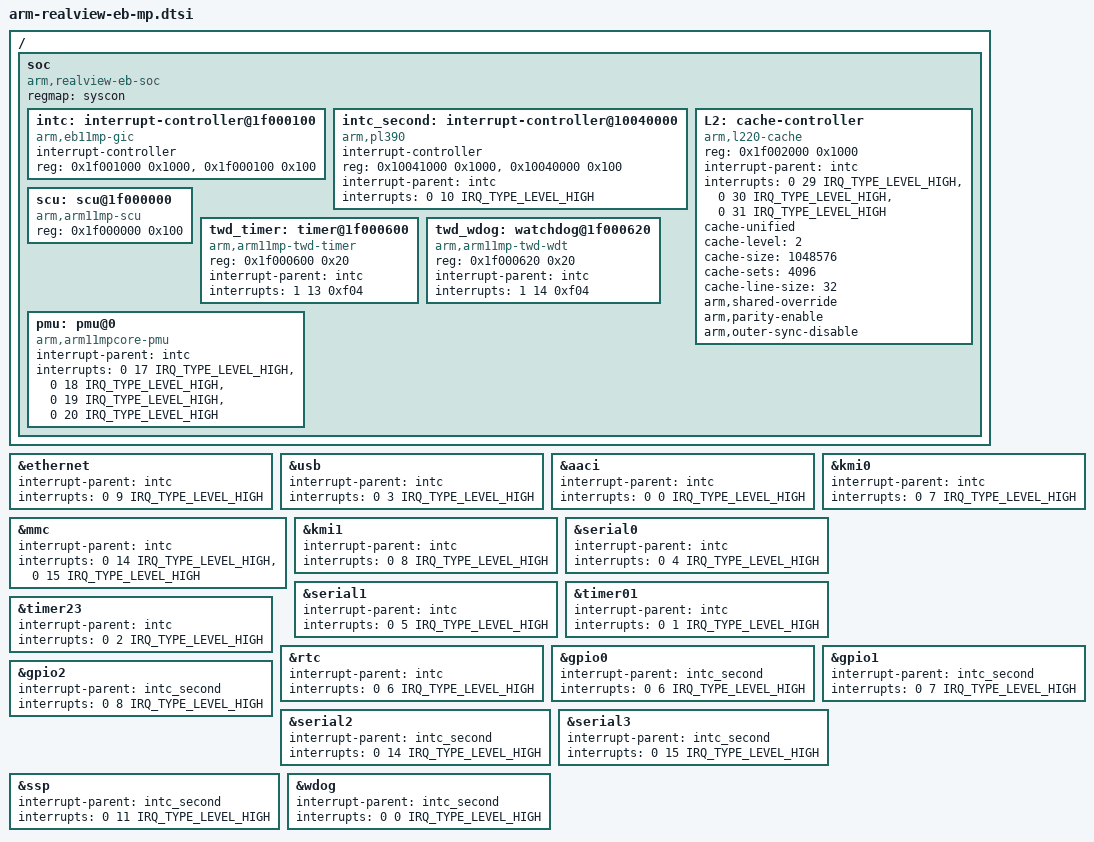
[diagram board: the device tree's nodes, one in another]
#include <dt-bindings/interrupt-controller/irq.h>
#include <dt-bindings/gpio/gpio.h>
#include "arm-realview-eb.dtsi"
/ {
	soc {
		#address-cells = <1>;
		#size-cells = <1>;
		compatible = "arm,realview-eb-soc", "simple-bus";
		regmap = <&syscon>;
		ranges;
		intc: interrupt-controller@1f000100 {
			compatible = "arm,eb11mp-gic";
			#interrupt-cells = <3>;
			#address-cells = <1>;
			interrupt-controller;
			reg = <0x1f001000 0x1000>,
			      <0x1f000100 0x100>;
		};
		intc_second: interrupt-controller@10040000 {
			compatible = "arm,pl390";
			#interrupt-cells = <3>;
			#address-cells = <1>;
			interrupt-controller;
			reg = <0x10041000 0x1000>,
			      <0x10040000 0x100>;
			interrupt-parent = <&intc>;
			interrupts = <0 10 IRQ_TYPE_LEVEL_HIGH>;
		};
		L2: cache-controller {
			compatible = "arm,l220-cache";
			reg = <0x1f002000 0x1000>;
			interrupt-parent = <&intc>;
			interrupts = <0 29 IRQ_TYPE_LEVEL_HIGH>,
			     <0 30 IRQ_TYPE_LEVEL_HIGH>,
			     <0 31 IRQ_TYPE_LEVEL_HIGH>;
			cache-unified;
			cache-level = <2>;
			cache-size = <1048576>;  
			cache-sets = <4096>;
			cache-line-size = <32>;
			arm,shared-override;
			arm,parity-enable;
			arm,outer-sync-disable;
		};
		scu: scu@1f000000 {
			compatible = "arm,arm11mp-scu";
			reg = <0x1f000000 0x100>;
		};
		twd_timer: timer@1f000600 {
			compatible = "arm,arm11mp-twd-timer";
			reg = <0x1f000600 0x20>;
			interrupt-parent = <&intc>;
			interrupts = <1 13 0xf04>;
		};
		twd_wdog: watchdog@1f000620 {
			compatible = "arm,arm11mp-twd-wdt";
			reg = <0x1f000620 0x20>;
			interrupt-parent = <&intc>;
			interrupts = <1 14 0xf04>;
		};
		pmu: pmu@0 {
			compatible = "arm,arm11mpcore-pmu";
			interrupt-parent = <&intc>;
			interrupts = <0 17 IRQ_TYPE_LEVEL_HIGH>,
			     <0 18 IRQ_TYPE_LEVEL_HIGH>,
			     <0 19 IRQ_TYPE_LEVEL_HIGH>,
			     <0 20 IRQ_TYPE_LEVEL_HIGH>;
		};
	};
};
&ethernet {
	interrupt-parent = <&intc>;
	interrupts = <0 9 IRQ_TYPE_LEVEL_HIGH>;
};
&usb {
	interrupt-parent = <&intc>;
	interrupts = <0 3 IRQ_TYPE_LEVEL_HIGH>;
};
&aaci {
	interrupt-parent = <&intc>;
	interrupts = <0 0 IRQ_TYPE_LEVEL_HIGH>;
};
&mmc {
	interrupt-parent = <&intc>;
	interrupts = <0 14 IRQ_TYPE_LEVEL_HIGH>,
			<0 15 IRQ_TYPE_LEVEL_HIGH>;
};
&kmi0 {
	interrupt-parent = <&intc>;
	interrupts = <0 7 IRQ_TYPE_LEVEL_HIGH>;
};
&kmi1 {
	interrupt-parent = <&intc>;
	interrupts = <0 8 IRQ_TYPE_LEVEL_HIGH>;
};
&serial0 {
	interrupt-parent = <&intc>;
	interrupts = <0 4 IRQ_TYPE_LEVEL_HIGH>;
};
&serial1 {
	interrupt-parent = <&intc>;
	interrupts = <0 5 IRQ_TYPE_LEVEL_HIGH>;
};
&timer01 {
	interrupt-parent = <&intc>;
	interrupts = <0 1 IRQ_TYPE_LEVEL_HIGH>;
};
&timer23 {
	interrupt-parent = <&intc>;
	interrupts = <0 2 IRQ_TYPE_LEVEL_HIGH>;
};
&rtc {
	interrupt-parent = <&intc>;
	interrupts = <0 6 IRQ_TYPE_LEVEL_HIGH>;
};
&gpio0 {
	interrupt-parent = <&intc_second>;
	interrupts = <0 6 IRQ_TYPE_LEVEL_HIGH>;
};
&gpio1 {
	interrupt-parent = <&intc_second>;
	interrupts = <0 7 IRQ_TYPE_LEVEL_HIGH>;
};
&gpio2 {
	interrupt-parent = <&intc_second>;
	interrupts = <0 8 IRQ_TYPE_LEVEL_HIGH>;
};
&serial2 {
	interrupt-parent = <&intc_second>;
	interrupts = <0 14 IRQ_TYPE_LEVEL_HIGH>;
	status = "okay";
};
&serial3 {
	interrupt-parent = <&intc_second>;
	interrupts = <0 15 IRQ_TYPE_LEVEL_HIGH>;
	status = "okay";
};
&ssp {
	interrupt-parent = <&intc_second>;
	interrupts = <0 11 IRQ_TYPE_LEVEL_HIGH>;
	status = "okay";
};
&wdog {
	interrupt-parent = <&intc_second>;
	interrupts = <0 0 IRQ_TYPE_LEVEL_HIGH>;
	status = "okay";
};
